AUTOSAR XML (schema 4-0-3)
standard types defined: Boolean, UInt8
package /AUTOSAR_Platform/DataConstrs
  range DC_Boolean: raw 0..1
  range DC_UInt8: raw 0..255
package /PATAC/EEPROM/BaseData
  base type PJB_EEP_Uint8: category=FIXED_LENGTH, base-type-size=8, base-type-encoding=NONE, native-declaration=unsigned char
package /PATAC/EEPROM/ImplementationDataType
  impl type EEP_Uint8: category=VALUE, base-type=PJB_EEP_Uint8, sw-calibration-access=READ-ONLY, type-emitter=RTE
package /PATAC/MSM/ComponentTypes
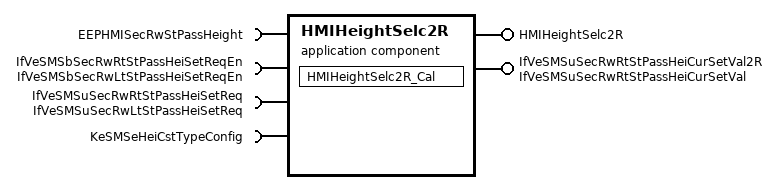
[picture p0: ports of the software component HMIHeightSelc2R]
  application sw component type HMIHeightSelc2R
    provide port HMIHeightSelc2R: server-com-spec{operation=Cal, queue-length=1}, provided-interface=HMIHeightSelc2R
    provide port IfVeSMSuSecRwRtStPassHeiCurSetVal2R: nonqueued-sender-com-spec{data-element=IfVeSMSuSecRwRtStPassHeiCurSetVal/Val, init-value=0}, provided-interface=IfVeSMSuSecRwRtStPassHeiCurSetVal
    4 x require port:
      EEPHMISecRwStPassHeight: required-com-specs=[Get, Set], required-interface=EEPHMISecRwStPassHeight
      IfVeSMSbSecRwRtStPassHeiSetReqEn: nonqueued-receiver-com-spec{data-element=IfVeSMSbSecRwLtStPassHeiSetReqEn/Val, filter=data-filter-type=ALWAYS, init-value=0}, required-interface=IfVeSMSbSecRwLtStPassHeiSetReqEn
      IfVeSMSuSecRwRtStPassHeiSetReq: nonqueued-receiver-com-spec{data-element=IfVeSMSuSecRwLtStPassHeiSetReq/Val, filter=data-filter-type=ALWAYS, init-value=0}, required-interface=IfVeSMSuSecRwLtStPassHeiSetReq
      KeSMSeHeiCstTypeConfig: parameter-require-com-spec{init-value=0, parameter=Val}, required-interface=KeSMSeHeiCstTypeConfig
    behavior HMIHeightSelc2R_InternalBehavior
      operation invoked event OIT_HMIHeightSelc2R_Cal_HMIHeightSelc2R_Cal: start-on-event=HMIHeightSelc2R_Cal, operation=HMIHeightSelc2R.Cal
      runnable HMIHeightSelc2R_Cal
        data-receive-point-by-arguments:
          access REC_IfVeSMSbSecRwRtStPassHeiSetReqEn_Val: accessed-variable=IfVeSMSbSecRwRtStPassHeiSetReqEn.Val
          access REC_IfVeSMSuSecRwRtStPassHeiSetReq_Val: accessed-variable=IfVeSMSuSecRwRtStPassHeiSetReq.Val
        data-send-points:
          access SEND_IfVeSMSuSecRwRtStPassHeiCurSetVal2R_Val: accessed-variable=IfVeSMSuSecRwRtStPassHeiCurSetVal2R.Val
        parameter access PA_KeSMSeHeiCstTypeConfig_Val: accessed-parameter=KeSMSeHeiCstTypeConfig.Val
        sync call SC_EEPHMISecRwStPassHeight_Get: operation=EEPHMISecRwStPassHeight.Get, timeout=0
        sync call SC_EEPHMISecRwStPassHeight_Set: operation=EEPHMISecRwStPassHeight.Set, timeout=0
  swc implementation HMIHeightSelc2R_Implementation: behavior=HMIHeightSelc2R_InternalBehavior
    code-descriptors:
      code Default: artifact-descriptors=autosar-engineering-object={short-label=Default, category=SWSRC}
package /PATAC/MSM/ModeAdjust/CalPortInterface
  parameter interface KeSMSeHeiCstTypeConfig
    parameter data prototype Val: sw-calibration-access=READ-WRITE, type=UInt8
package /PATAC/MSM/ModeAdjust/PortInterface
  client server interface EEPHMISecRwStPassHeight
    operation Get
      arg arg: type=EEP_Uint8, direction=OUT, server-argument-impl-policy=USE-ARGUMENT-TYPE
    operation Set
      arg arg: type=EEP_Uint8, direction=IN, server-argument-impl-policy=USE-ARGUMENT-TYPE
  client server interface HMIHeightSelc2R
    operation Cal
  sender receiver interface IfVeSMSbSecRwLtStPassHeiSetReqEn: invalidation-policy{data-element=IfVeSMSbSecRwLtStPassHeiSetReqEn/Val, handle-invalid=DONT-INVALIDATE}
    data Val: type=Boolean
  sender receiver interface IfVeSMSuSecRwLtStPassHeiSetReq: invalidation-policy{data-element=IfVeSMSuSecRwLtStPassHeiSetReq/Val, handle-invalid=DONT-INVALIDATE}
    data Val: type=UInt8
  sender receiver interface IfVeSMSuSecRwRtStPassHeiCurSetVal: invalidation-policy{data-element=IfVeSMSuSecRwRtStPassHeiCurSetVal/Val, handle-invalid=DONT-INVALIDATE}
    data Val: type=UInt8
